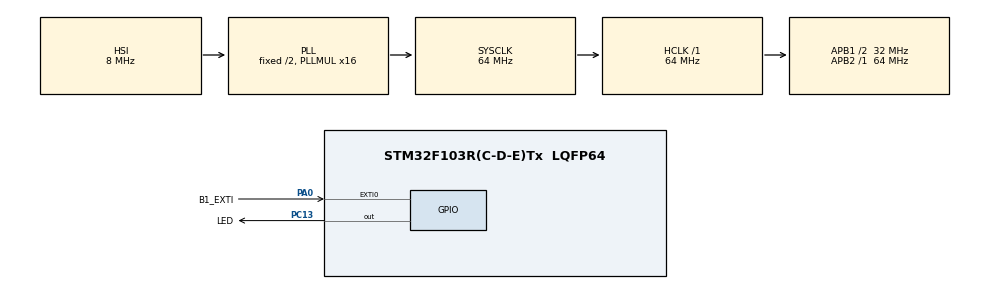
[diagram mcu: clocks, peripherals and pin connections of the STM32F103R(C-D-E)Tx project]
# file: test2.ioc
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Mcu.Family=STM32F1
Mcu.Name=STM32F103R(C-D-E)Tx
Mcu.Package=LQFP64
NVIC.EXTI0_IRQn=true\:1\:0\:true\:false\:true\:true\:true
NVIC.PriorityGroup=NVIC_PRIORITYGROUP_4
PA0-WKUP.GPIO_Label=B1_EXTI
PA0-WKUP.GPIO_ModeDefaultEXTI=GPIO_MODE_IT_FALLING
PA0-WKUP.Signal=GPXTI0
PA13.Mode=Serial_Wire
PA13.Signal=SYS_JTMS-SWDIO
PA14.Mode=Serial_Wire
PA14.Signal=SYS_JTCK-SWCLK
PC13-TAMPER-RTC.GPIO_Label=LED
PC13-TAMPER-RTC.Signal=GPIO_Output
PD0-OSC_IN.Mode=HSE-External-Oscillator
PD0-OSC_IN.Signal=RCC_OSC_IN
PD1-OSC_OUT.Mode=HSE-External-Oscillator
PD1-OSC_OUT.Signal=RCC_OSC_OUT
ProjectManager.HeapSize=0x200
ProjectManager.StackSize=0x400
ProjectManager.TargetToolchain=MDK-ARM V5.27
RCC.AHBFreq_Value=64000000
RCC.APB1CLKDivider=RCC_HCLK_DIV2
RCC.APB1Freq_Value=32000000
RCC.APB1TimFreq_Value=64000000
RCC.APB2Freq_Value=64000000
RCC.APB2TimFreq_Value=64000000
RCC.HCLKFreq_Value=64000000
RCC.PLLMUL=RCC_PLL_MUL16
RCC.SYSCLKFreq_VALUE=64000000
RCC.SYSCLKSource=RCC_SYSCLKSOURCE_PLLCLK
RCC.USBFreq_Value=64000000
board=custom

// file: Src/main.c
/* USER CODE BEGIN Header */
/**
  ******************************************************************************
  * @file           : main.c
  * @brief          : Main program body
  ******************************************************************************
  * @attention
  *
  * <h2><center>&copy; Copyright (c) 2021 STMicroelectronics.
  * All rights reserved.</center></h2>
  *
  * This software component is licensed by ST under BSD 3-Clause license,
  * the "License"; You may not use this file except in compliance with the
  * License. You may obtain a copy of the License at:
  *                        opensource.org/licenses/BSD-3-Clause
  *
  ******************************************************************************
  */
/* USER CODE END Header */

#include "main.h"
#include "gpio.h"

/* USER CODE BEGIN PV */
volatile uint8_t flag = 0;
/* USER CODE END PV */

void SystemClock_Config(void);

int main(void)
{

  /* MCU Configuration--------------------------------------------------------*/

  /* Reset of all peripherals, Initializes the Flash interface and the Systick. */
  HAL_Init();

  /* Configure the system clock */
  SystemClock_Config();

  /* Initialize all configured peripherals */
  MX_GPIO_Init();

  /* Infinite loop */
  while (1)
  {

		if(flag == 0)
		{
			HAL_GPIO_WritePin(LED_GPIO_Port, LED_Pin, GPIO_PIN_RESET);
			HAL_Delay(1000);
			HAL_GPIO_WritePin(LED_GPIO_Port, LED_Pin, GPIO_PIN_SET);
			HAL_Delay(1000);
		}
		else if(flag == 1)
		{
			HAL_GPIO_WritePin(LED_GPIO_Port, LED_Pin, GPIO_PIN_RESET);
			HAL_Delay(50);
			HAL_GPIO_WritePin(LED_GPIO_Port, LED_Pin, GPIO_PIN_SET);
			HAL_Delay(1000);
		}
		else
		{
			HAL_GPIO_WritePin(LED_GPIO_Port, LED_Pin, GPIO_PIN_RESET);
		}
  }
}

void SystemClock_Config(void)
{
  RCC_OscInitTypeDef RCC_OscInitStruct = {0};
  RCC_ClkInitTypeDef RCC_ClkInitStruct = {0};

  /** Initializes the CPU, AHB and APB busses clocks
  */
  RCC_OscInitStruct.OscillatorType = RCC_OSCILLATORTYPE_HSI;
  RCC_OscInitStruct.HSIState = RCC_HSI_ON;
  RCC_OscInitStruct.HSICalibrationValue = RCC_HSICALIBRATION_DEFAULT;
  RCC_OscInitStruct.PLL.PLLState = RCC_PLL_ON;
  RCC_OscInitStruct.PLL.PLLSource = RCC_PLLSOURCE_HSI_DIV2;
  RCC_OscInitStruct.PLL.PLLMUL = RCC_PLL_MUL16;
  if (HAL_RCC_OscConfig(&RCC_OscInitStruct) != HAL_OK)
  {
    Error_Handler();
  }
  /** Initializes the CPU, AHB and APB busses clocks
  */
  RCC_ClkInitStruct.ClockType = RCC_CLOCKTYPE_HCLK|RCC_CLOCKTYPE_SYSCLK
                              |RCC_CLOCKTYPE_PCLK1|RCC_CLOCKTYPE_PCLK2;
  RCC_ClkInitStruct.SYSCLKSource = RCC_SYSCLKSOURCE_PLLCLK;
  RCC_ClkInitStruct.AHBCLKDivider = RCC_SYSCLK_DIV1;
  RCC_ClkInitStruct.APB1CLKDivider = RCC_HCLK_DIV2;
  RCC_ClkInitStruct.APB2CLKDivider = RCC_HCLK_DIV1;

  if (HAL_RCC_ClockConfig(&RCC_ClkInitStruct, FLASH_LATENCY_2) != HAL_OK)
  {
    Error_Handler();
  }
}

/* USER CODE BEGIN 4 */
void HAL_GPIO_Callback(uint16_t GPIO_Pin)
{
	if(GPIO_Pin == B1_EXTI_Pin)
	{
		flag = (++flag)%3;
	}
}
/* USER CODE END 4 */

void Error_Handler(void)
{
}

/************************ (C) COPYRIGHT STMicroelectronics *****END OF FILE****/
